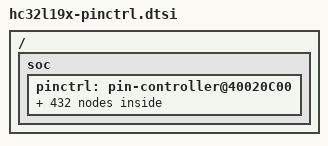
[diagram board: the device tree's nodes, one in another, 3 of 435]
/* Generated by gen-pinctrl.perl, do not edit this file. */
#include <hc32/hc32l19x-pinctrl.h>
/ {
	soc {
		pinctrl: pin-controller@40020C00 {
			/omit-if-no-ref/ uart1_cts_pa0: uart1_cts_pa0 {
				pinmux = <PA00_UART1_CTS>;
			};
			/omit-if-no-ref/ uart1_rts_pa1: uart1_rts_pa1 {
				pinmux = <PA01_UART1_RTS>;
			};
			/omit-if-no-ref/ uart1_txd_pa2: uart1_txd_pa2 {
				pinmux = <PA02_UART1_TXD>;
			};
			/omit-if-no-ref/ uart1_rxd_pa3: uart1_rxd_pa3 {
				pinmux = <PA03_UART1_RXD>;
			};
			/omit-if-no-ref/ spi0_cs_pa4: spi0_cs_pa4 {
				pinmux = <PA04_SPI0_CS>;
				bias-pull-down;
			};
			/omit-if-no-ref/ spi0_sck_pa5: spi0_sck_pa5 {
				pinmux = <PA05_SPI0_SCK>;
				bias-pull-down;
			};
			/omit-if-no-ref/ spi0_miso_pa6: spi0_miso_pa6 {
				pinmux = <PA06_SPI0_MISO>;
				bias-pull-down;
			};
			/omit-if-no-ref/ spi0_mosi_pa7: spi0_mosi_pa7 {
				pinmux = <PA07_SPI0_MOSI>;
				bias-pull-down;
			};
			/omit-if-no-ref/ uart0_txd_pa8: uart0_txd_pa8 {
				pinmux = <PA08_UART0_TXD>;
			};
			/omit-if-no-ref/ uart0_txd_pa9: uart0_txd_pa9 {
				pinmux = <PA09_UART0_TXD>;
			};
			/omit-if-no-ref/ uart0_rxd_pa10: uart0_rxd_pa10 {
				pinmux = <PA10_UART0_RXD>;
			};
			/omit-if-no-ref/ uart0_cts_pa11: uart0_cts_pa11 {
				pinmux = <PA11_UART0_CTS>;
			};
			/omit-if-no-ref/ uart0_rts_pa12: uart0_rts_pa12 {
				pinmux = <PA12_UART0_RTS>;
			};
			/omit-if-no-ref/ ir_out_pa13: ir_out_pa13 {
				pinmux = <PA13_IR_OUT>;
			};
			/omit-if-no-ref/ uart1_txd_pa14: uart1_txd_pa14 {
				pinmux = <PA14_UART1_TXD>;
			};
			/omit-if-no-ref/ spi0_cs_pa15: spi0_cs_pa15 {
				pinmux = <PA15_SPI0_CS>;
				bias-pull-down;
			};
			/omit-if-no-ref/ pca_ch2_pb0: pca_ch2_pb0 {
				pinmux = <PB00_PCA_CH2>;
			};
			/omit-if-no-ref/ pca_ch3_pb1: pca_ch3_pb1 {
				pinmux = <PB01_PCA_CH3>;
			};
			/omit-if-no-ref/ lptim_tog_pb2: lptim_tog_pb2 {
				pinmux = <PB02_LPTIM_TOG>;
			};
			/omit-if-no-ref/ spi0_sck_pb3: spi0_sck_pb3 {
				pinmux = <PB03_SPI0_SCK>;
				bias-pull-down;
			};
			/omit-if-no-ref/ spi0_miso_pb4: spi0_miso_pb4 {
				pinmux = <PB04_SPI0_MISO>;
				bias-pull-down;
			};
			/omit-if-no-ref/ spi0_mosi_pb5: spi0_mosi_pb5 {
				pinmux = <PB05_SPI0_MOSI>;
				bias-pull-down;
			};
			/omit-if-no-ref/ i2c0_scl_pb6: i2c0_scl_pb6 {
				pinmux = <PB06_I2C0_SCL>;
				bias-pull-up;
				drive-open-drain;
			};
			/omit-if-no-ref/ i2c0_sda_pb7: i2c0_sda_pb7 {
				pinmux = <PB07_I2C0_SDA>;
				bias-pull-up;
				drive-open-drain;
			};
			/omit-if-no-ref/ i2c0_scl_pb8: i2c0_scl_pb8 {
				pinmux = <PB08_I2C0_SCL>;
				bias-pull-up;
				drive-open-drain;
			};
			/omit-if-no-ref/ i2c0_sda_pb9: i2c0_sda_pb9 {
				pinmux = <PB09_I2C0_SDA>;
				bias-pull-up;
				drive-open-drain;
			};
			/omit-if-no-ref/ i2c1_scl_pb10: i2c1_scl_pb10 {
				pinmux = <PB10_I2C1_SCL>;
				bias-pull-up;
				drive-open-drain;
			};
			/omit-if-no-ref/ i2c1_sda_pb11: i2c1_sda_pb11 {
				pinmux = <PB11_I2C1_SDA>;
				bias-pull-up;
				drive-open-drain;
			};
			/omit-if-no-ref/ spi1_cs_pb12: spi1_cs_pb12 {
				pinmux = <PB12_SPI1_CS>;
				bias-pull-down;
			};
			/omit-if-no-ref/ spi1_sck_pb13: spi1_sck_pb13 {
				pinmux = <PB13_SPI1_SCK>;
				bias-pull-down;
			};
			/omit-if-no-ref/ spi1_miso_pb14: spi1_miso_pb14 {
				pinmux = <PB14_SPI1_MISO>;
				bias-pull-down;
			};
			/omit-if-no-ref/ spi1_mosi_pb15: spi1_mosi_pb15 {
				pinmux = <PB15_SPI1_MOSI>;
				bias-pull-down;
			};
			/omit-if-no-ref/ lptim_gate_pc0: lptim_gate_pc0 {
				pinmux = <PC00_LPTIM_GATE>;
			};
			/omit-if-no-ref/ lptim_tog_pc1: lptim_tog_pc1 {
				pinmux = <PC01_LPTIM_TOG>;
			};
			/omit-if-no-ref/ spi1_miso_pc2: spi1_miso_pc2 {
				pinmux = <PC02_SPI1_MISO>;
				bias-pull-down;
			};
			/omit-if-no-ref/ spi1_mosi_pc3: spi1_mosi_pc3 {
				pinmux = <PC03_SPI1_MOSI>;
				bias-pull-down;
			};
			/omit-if-no-ref/ lpuart0_txd_pc4: lpuart0_txd_pc4 {
				pinmux = <PC04_LPUART0_TXD>;
			};
			/omit-if-no-ref/ lpuart0_rxd_pc5: lpuart0_rxd_pc5 {
				pinmux = <PC05_LPUART0_RXD>;
			};
			/omit-if-no-ref/ pca_ch0_pc6: pca_ch0_pc6 {
				pinmux = <PC06_PCA_CH0>;
			};
			/omit-if-no-ref/ pca_ch1_pc7: pca_ch1_pc7 {
				pinmux = <PC07_PCA_CH1>;
			};
			/omit-if-no-ref/ pca_ch2_pc8: pca_ch2_pc8 {
				pinmux = <PC08_PCA_CH2>;
			};
			/omit-if-no-ref/ pca_ch3_pc9: pca_ch3_pc9 {
				pinmux = <PC09_PCA_CH3>;
			};
			/omit-if-no-ref/ lpuart1_txd_pc10: lpuart1_txd_pc10 {
				pinmux = <PC10_LPUART1_TXD>;
			};
			/omit-if-no-ref/ lpuart1_rxd_pc11: lpuart1_rxd_pc11 {
				pinmux = <PC11_LPUART1_RXD>;
			};
			/omit-if-no-ref/ lpuart0_txd_pc12: lpuart0_txd_pc12 {
				pinmux = <PC12_LPUART0_TXD>;
			};
			/omit-if-no-ref/ pca_eci_pd2: pca_eci_pd2 {
				pinmux = <PD02_PCA_ECI>;
			};
			/omit-if-no-ref/ uart1_cts_pd3: uart1_cts_pd3 {
				pinmux = <PD03_UART1_CTS>;
			};
			/omit-if-no-ref/ uart1_rts_pd4: uart1_rts_pd4 {
				pinmux = <PD04_UART1_RTS>;
			};
			/omit-if-no-ref/ uart1_txd_pd5: uart1_txd_pd5 {
				pinmux = <PD05_UART1_TXD>;
			};
			/omit-if-no-ref/ uart1_rxd_pd6: uart1_rxd_pd6 {
				pinmux = <PD06_UART1_RXD>;
			};
			/omit-if-no-ref/ uart1_txd_pd7: uart1_txd_pd7 {
				pinmux = <PD07_UART1_TXD>;
			};
			/omit-if-no-ref/ lpuart0_txd_pd8: lpuart0_txd_pd8 {
				pinmux = <PD08_LPUART0_TXD>;
			};
			/omit-if-no-ref/ lpuart0_rxd_pd9: lpuart0_rxd_pd9 {
				pinmux = <PD09_LPUART0_RXD>;
			};
			/omit-if-no-ref/ lpuart0_txd_pd10: lpuart0_txd_pd10 {
				pinmux = <PD10_LPUART0_TXD>;
			};
			/omit-if-no-ref/ lpuart0_cts_pd11: lpuart0_cts_pd11 {
				pinmux = <PD11_LPUART0_CTS>;
			};
			/omit-if-no-ref/ lpuart0_rts_pd12: lpuart0_rts_pd12 {
				pinmux = <PD12_LPUART0_RTS>;
			};
			/omit-if-no-ref/ uart2_rxd_pd13: uart2_rxd_pd13 {
				pinmux = <PD13_UART2_RXD>;
			};
			/omit-if-no-ref/ uart2_txd_pd14: uart2_txd_pd14 {
				pinmux = <PD14_UART2_TXD>;
			};
			/omit-if-no-ref/ tim1_cha_pe0: tim1_cha_pe0 {
				pinmux = <PE00_TIM1_CHA>;
			};
			/omit-if-no-ref/ tim2_cha_pe1: tim2_cha_pe1 {
				pinmux = <PE01_TIM2_CHA>;
			};
			/omit-if-no-ref/ pca_eci_pe2: pca_eci_pe2 {
				pinmux = <PE02_PCA_ECI>;
			};
			/omit-if-no-ref/ pca_ch0_pe3: pca_ch0_pe3 {
				pinmux = <PE03_PCA_CH0>;
			};
			/omit-if-no-ref/ pca_ch1_pe4: pca_ch1_pe4 {
				pinmux = <PE04_PCA_CH1>;
			};
			/omit-if-no-ref/ pca_ch2_pe5: pca_ch2_pe5 {
				pinmux = <PE05_PCA_CH2>;
			};
			/omit-if-no-ref/ pca_ch3_pe6: pca_ch3_pe6 {
				pinmux = <PE06_PCA_CH3>;
			};
			/omit-if-no-ref/ tim3_etr_pe7: tim3_etr_pe7 {
				pinmux = <PE07_TIM3_ETR>;
			};
			/omit-if-no-ref/ tim3_ch0b_pe8: tim3_ch0b_pe8 {
				pinmux = <PE08_TIM3_CH0B>;
			};
			/omit-if-no-ref/ tim3_ch0a_pe9: tim3_ch0a_pe9 {
				pinmux = <PE09_TIM3_CH0A>;
			};
			/omit-if-no-ref/ tim3_ch1b_pe10: tim3_ch1b_pe10 {
				pinmux = <PE10_TIM3_CH1B>;
			};
			/omit-if-no-ref/ tim3_ch1a_pe11: tim3_ch1a_pe11 {
				pinmux = <PE11_TIM3_CH1A>;
			};
			/omit-if-no-ref/ tim3_ch2b_pe12: tim3_ch2b_pe12 {
				pinmux = <PE12_TIM3_CH2B>;
			};
			/omit-if-no-ref/ tim3_ch2a_pe13: tim3_ch2a_pe13 {
				pinmux = <PE13_TIM3_CH2A>;
			};
			/omit-if-no-ref/ tim3_ch0b_pe14: tim3_ch0b_pe14 {
				pinmux = <PE14_TIM3_CH0B>;
			};
			/omit-if-no-ref/ tim3_bk_pe15: tim3_bk_pe15 {
				pinmux = <PE15_TIM3_BK>;
			};
			/omit-if-no-ref/ i2c0_sda_pf0: i2c0_sda_pf0 {
				pinmux = <PF00_I2C0_SDA>;
				bias-pull-up;
				drive-open-drain;
			};
			/omit-if-no-ref/ i2c0_scl_pf1: i2c0_scl_pf1 {
				pinmux = <PF01_I2C0_SCL>;
				bias-pull-up;
				drive-open-drain;
			};
			/omit-if-no-ref/ i2c1_scl_pf6: i2c1_scl_pf6 {
				pinmux = <PF06_I2C1_SCL>;
				bias-pull-up;
				drive-open-drain;
			};
			/omit-if-no-ref/ i2c1_sda_pf7: i2c1_sda_pf7 {
				pinmux = <PF07_I2C1_SDA>;
				bias-pull-up;
				drive-open-drain;
			};
			/omit-if-no-ref/ tim0_cha_pf9: tim0_cha_pf9 {
				pinmux = <PF09_TIM0_CHA>;
			};
			/omit-if-no-ref/ tim0_chb_pf10: tim0_chb_pf10 {
				pinmux = <PF10_TIM0_CHB>;
			};
			/omit-if-no-ref/ lpuart1_txd_pa0: lpuart1_txd_pa0 {
				pinmux = <PA00_LPUART1_TXD>;
			};
			/omit-if-no-ref/ lpuart1_rxd_pa1: lpuart1_rxd_pa1 {
				pinmux = <PA01_LPUART1_RXD>;
			};
			/omit-if-no-ref/ tim0_cha_pa2: tim0_cha_pa2 {
				pinmux = <PA02_TIM0_CHA>;
			};
			/omit-if-no-ref/ tim0_gate_pa3: tim0_gate_pa3 {
				pinmux = <PA03_TIM0_GATE>;
			};
			/omit-if-no-ref/ uart1_txd_pa4: uart1_txd_pa4 {
				pinmux = <PA04_UART1_TXD>;
			};
			/omit-if-no-ref/ tim0_etr_pa5: tim0_etr_pa5 {
				pinmux = <PA05_TIM0_ETR>;
			};
			/omit-if-no-ref/ pca_ch0_pa6: pca_ch0_pa6 {
				pinmux = <PA06_PCA_CH0>;
			};
			/omit-if-no-ref/ pca_ch1_pa7: pca_ch1_pa7 {
				pinmux = <PA07_PCA_CH1>;
			};
			/omit-if-no-ref/ tim3_ch0a_pa8: tim3_ch0a_pa8 {
				pinmux = <PA08_TIM3_CH0A>;
			};
			/omit-if-no-ref/ tim3_ch1a_pa9: tim3_ch1a_pa9 {
				pinmux = <PA09_TIM3_CH1A>;
			};
			/omit-if-no-ref/ tim3_ch2a_pa10: tim3_ch2a_pa10 {
				pinmux = <PA10_TIM3_CH2A>;
			};
			/omit-if-no-ref/ tim3_gate_pa11: tim3_gate_pa11 {
				pinmux = <PA11_TIM3_GATE>;
			};
			/omit-if-no-ref/ tim3_etr_pa12: tim3_etr_pa12 {
				pinmux = <PA12_TIM3_ETR>;
			};
			/omit-if-no-ref/ uart0_rxd_pa13: uart0_rxd_pa13 {
				pinmux = <PA13_UART0_RXD>;
			};
			/omit-if-no-ref/ uart0_txd_pa14: uart0_txd_pa14 {
				pinmux = <PA14_UART0_TXD>;
			};
			/omit-if-no-ref/ uart1_rxd_pa15: uart1_rxd_pa15 {
				pinmux = <PA15_UART1_RXD>;
			};
			/omit-if-no-ref/ tim3_ch1b_pb0: tim3_ch1b_pb0 {
				pinmux = <PB00_TIM3_CH1B>;
			};
			/omit-if-no-ref/ pclk_out_pb1: pclk_out_pb1 {
				pinmux = <PB01_PCLK_OUT>;
			};
			/omit-if-no-ref/ pca_eci_pb2: pca_eci_pb2 {
				pinmux = <PB02_PCA_ECI>;
			};
			/omit-if-no-ref/ tim0_chb_pb3: tim0_chb_pb3 {
				pinmux = <PB03_TIM0_CHB>;
			};
			/omit-if-no-ref/ pca_ch0_pb4: pca_ch0_pb4 {
				pinmux = <PB04_PCA_CH0>;
			};
			/omit-if-no-ref/ uart0_txd_pb6: uart0_txd_pb6 {
				pinmux = <PB06_UART0_TXD>;
			};
			/omit-if-no-ref/ uart0_rxd_pb7: uart0_rxd_pb7 {
				pinmux = <PB07_UART0_RXD>;
			};
			/omit-if-no-ref/ tim1_cha_pb8: tim1_cha_pb8 {
				pinmux = <PB08_TIM1_CHA>;
			};
			/omit-if-no-ref/ ir_out_pb9: ir_out_pb9 {
				pinmux = <PB09_IR_OUT>;
			};
			/omit-if-no-ref/ spi1_sck_pb10: spi1_sck_pb10 {
				pinmux = <PB10_SPI1_SCK>;
				bias-pull-down;
			};
			/omit-if-no-ref/ tim1_chb_pb11: tim1_chb_pb11 {
				pinmux = <PB11_TIM1_CHB>;
			};
			/omit-if-no-ref/ tim3_bk_pb12: tim3_bk_pb12 {
				pinmux = <PB12_TIM3_BK>;
			};
			/omit-if-no-ref/ i2c1_scl_pb13: i2c1_scl_pb13 {
				pinmux = <PB13_I2C1_SCL>;
				bias-pull-up;
				drive-open-drain;
			};
			/omit-if-no-ref/ i2c1_sda_pb14: i2c1_sda_pb14 {
				pinmux = <PB14_I2C1_SDA>;
				bias-pull-up;
				drive-open-drain;
			};
			/omit-if-no-ref/ tim3_ch2b_pb15: tim3_ch2b_pb15 {
				pinmux = <PB15_TIM3_CH2B>;
			};
			/omit-if-no-ref/ pcnt_s0_pc0: pcnt_s0_pc0 {
				pinmux = <PC00_PCNT_S0>;
			};
			/omit-if-no-ref/ tim5_chb_pc1: tim5_chb_pc1 {
				pinmux = <PC01_TIM5_CHB>;
			};
			/omit-if-no-ref/ lptim_togn_pc2: lptim_togn_pc2 {
				pinmux = <PC02_LPTIM_TOGN>;
			};
			/omit-if-no-ref/ lptim_etr_pc3: lptim_etr_pc3 {
				pinmux = <PC03_LPTIM_ETR>;
			};
			/omit-if-no-ref/ tim2_etr_pc4: tim2_etr_pc4 {
				pinmux = <PC04_TIM2_ETR>;
			};
			/omit-if-no-ref/ tim6_chb_pc5: tim6_chb_pc5 {
				pinmux = <PC05_TIM6_CHB>;
			};
			/omit-if-no-ref/ tim4_cha_pc6: tim4_cha_pc6 {
				pinmux = <PC06_TIM4_CHA>;
			};
			/omit-if-no-ref/ tim5_cha_pc7: tim5_cha_pc7 {
				pinmux = <PC07_TIM5_CHA>;
			};
			/omit-if-no-ref/ tim6_cha_pc8: tim6_cha_pc8 {
				pinmux = <PC08_TIM6_CHA>;
			};
			/omit-if-no-ref/ tim4_chb_pc9: tim4_chb_pc9 {
				pinmux = <PC09_TIM4_CHB>;
			};
			/omit-if-no-ref/ lpuart0_txd_pc10: lpuart0_txd_pc10 {
				pinmux = <PC10_LPUART0_TXD>;
			};
			/omit-if-no-ref/ lpuart0_rxd_pc11: lpuart0_rxd_pc11 {
				pinmux = <PC11_LPUART0_RXD>;
			};
			/omit-if-no-ref/ lpuart1_txd_pc12: lpuart1_txd_pc12 {
				pinmux = <PC12_LPUART1_TXD>;
			};
			/omit-if-no-ref/ rtc_1hz_pc13: rtc_1hz_pc13 {
				pinmux = <PC13_RTC_1HZ>;
			};
			/omit-if-no-ref/ spi1_cs_pd0: spi1_cs_pd0 {
				pinmux = <PD00_SPI1_CS>;
				bias-pull-down;
			};
			/omit-if-no-ref/ spi1_sck_pd1: spi1_sck_pd1 {
				pinmux = <PD01_SPI1_SCK>;
				bias-pull-down;
			};
			/omit-if-no-ref/ lpuart0_rts_pd2: lpuart0_rts_pd2 {
				pinmux = <PD02_LPUART0_RTS>;
			};
			/omit-if-no-ref/ spi1_miso_pd3: spi1_miso_pd3 {
				pinmux = <PD03_SPI1_MISO>;
				bias-pull-down;
			};
			/omit-if-no-ref/ spi1_mosi_pd4: spi1_mosi_pd4 {
				pinmux = <PD04_SPI1_MOSI>;
				bias-pull-down;
			};
			/omit-if-no-ref/ lptim1_gate_pd5: lptim1_gate_pd5 {
				pinmux = <PD05_LPTIM1_GATE>;
			};
			/omit-if-no-ref/ lptim1_etr_pd6: lptim1_etr_pd6 {
				pinmux = <PD06_LPTIM1_ETR>;
			};
			/omit-if-no-ref/ uart2_rts_pd12: uart2_rts_pd12 {
				pinmux = <PD12_UART2_RTS>;
			};
			/omit-if-no-ref/ uart2_cts_pd15: uart2_cts_pd15 {
				pinmux = <PD15_UART2_CTS>;
			};
			/omit-if-no-ref/ lptim1_gate_pe7: lptim1_gate_pe7 {
				pinmux = <PE07_LPTIM1_GATE>;
			};
			/omit-if-no-ref/ lptim1_etr_pe8: lptim1_etr_pe8 {
				pinmux = <PE08_LPTIM1_ETR>;
			};
			/omit-if-no-ref/ lptim1_tog_pe9: lptim1_tog_pe9 {
				pinmux = <PE09_LPTIM1_TOG>;
			};
			/omit-if-no-ref/ lptim1_togn_pe10: lptim1_togn_pe10 {
				pinmux = <PE10_LPTIM1_TOGN>;
			};
			/omit-if-no-ref/ spi0_cs_pe12: spi0_cs_pe12 {
				pinmux = <PE12_SPI0_CS>;
				bias-pull-down;
			};
			/omit-if-no-ref/ spi0_sck_pe13: spi0_sck_pe13 {
				pinmux = <PE13_SPI0_SCK>;
				bias-pull-down;
			};
			/omit-if-no-ref/ spi0_miso_pe14: spi0_miso_pe14 {
				pinmux = <PE14_SPI0_MISO>;
				bias-pull-down;
			};
			/omit-if-no-ref/ spi0_mosi_pe15: spi0_mosi_pe15 {
				pinmux = <PE15_SPI0_MOSI>;
				bias-pull-down;
			};
			/omit-if-no-ref/ tim4_chb_pf1: tim4_chb_pf1 {
				pinmux = <PF01_TIM4_CHB>;
			};
			/omit-if-no-ref/ lpuart1_cts_pf6: lpuart1_cts_pf6 {
				pinmux = <PF06_LPUART1_CTS>;
			};
			/omit-if-no-ref/ lpuart1_rts_pf7: lpuart1_rts_pf7 {
				pinmux = <PF07_LPUART1_RTS>;
			};
			/omit-if-no-ref/ tim0_etr_pa0: tim0_etr_pa0 {
				pinmux = <PA00_TIM0_ETR>;
			};
			/omit-if-no-ref/ tim0_chb_pa1: tim0_chb_pa1 {
				pinmux = <PA01_TIM0_CHB>;
			};
			/omit-if-no-ref/ vc1_out_pa2: vc1_out_pa2 {
				pinmux = <PA02_VC1_OUT>;
			};
			/omit-if-no-ref/ tim1_chb_pa3: tim1_chb_pa3 {
				pinmux = <PA03_TIM1_CHB>;
			};
			/omit-if-no-ref/ pca_ch4_pa4: pca_ch4_pa4 {
				pinmux = <PA04_PCA_CH4>;
			};
			/omit-if-no-ref/ pca_eci_pa5: pca_eci_pa5 {
				pinmux = <PA05_PCA_ECI>;
			};
			/omit-if-no-ref/ tim3_bk_pa6: tim3_bk_pa6 {
				pinmux = <PA06_TIM3_BK>;
			};
			/omit-if-no-ref/ hclk_out_pa7: hclk_out_pa7 {
				pinmux = <PA07_HCLK_OUT>;
			};
			/omit-if-no-ref/ tim0_bk_pa9: tim0_bk_pa9 {
				pinmux = <PA09_TIM0_BK>;
			};
			/omit-if-no-ref/ tim2_bk_pa10: tim2_bk_pa10 {
				pinmux = <PA10_TIM2_BK>;
			};
			/omit-if-no-ref/ i2c1_scl_pa11: i2c1_scl_pa11 {
				pinmux = <PA11_I2C1_SCL>;
				bias-pull-up;
				drive-open-drain;
			};
			/omit-if-no-ref/ i2c1_sda_pa12: i2c1_sda_pa12 {
				pinmux = <PA12_I2C1_SDA>;
				bias-pull-up;
				drive-open-drain;
			};
			/omit-if-no-ref/ lvd_out_pa13: lvd_out_pa13 {
				pinmux = <PA13_LVD_OUT>;
			};
			/omit-if-no-ref/ tim3_ch2a_pa14: tim3_ch2a_pa14 {
				pinmux = <PA14_TIM3_CH2A>;
			};
			/omit-if-no-ref/ lpuart1_rts_pa15: lpuart1_rts_pa15 {
				pinmux = <PA15_LPUART1_RTS>;
			};
			/omit-if-no-ref/ lpuart0_txd_pb0: lpuart0_txd_pb0 {
				pinmux = <PB00_LPUART0_TXD>;
			};
			/omit-if-no-ref/ tim3_ch2b_pb1: tim3_ch2b_pb1 {
				pinmux = <PB01_TIM3_CH2B>;
			};
			/omit-if-no-ref/ lpuart1_txd_pb2: lpuart1_txd_pb2 {
				pinmux = <PB02_LPUART1_TXD>;
			};
			/omit-if-no-ref/ tim1_gate_pb3: tim1_gate_pb3 {
				pinmux = <PB03_TIM1_GATE>;
			};
			/omit-if-no-ref/ tim2_bk_pb4: tim2_bk_pb4 {
				pinmux = <PB04_TIM2_BK>;
			};
			/omit-if-no-ref/ tim1_bk_pb5: tim1_bk_pb5 {
				pinmux = <PB05_TIM1_BK>;
			};
			/omit-if-no-ref/ tim1_chb_pb6: tim1_chb_pb6 {
				pinmux = <PB06_TIM1_CHB>;
			};
			/omit-if-no-ref/ tim2_chb_pb7: tim2_chb_pb7 {
				pinmux = <PB07_TIM2_CHB>;
			};
			/omit-if-no-ref/ spi1_cs_pb9: spi1_cs_pb9 {
				pinmux = <PB09_SPI1_CS>;
				bias-pull-down;
			};
			/omit-if-no-ref/ tim1_cha_pb10: tim1_cha_pb10 {
				pinmux = <PB10_TIM1_CHA>;
			};
			/omit-if-no-ref/ lpuart0_rxd_pb11: lpuart0_rxd_pb11 {
				pinmux = <PB11_LPUART0_RXD>;
			};
			/omit-if-no-ref/ lpuart0_txd_pb12: lpuart0_txd_pb12 {
				pinmux = <PB12_LPUART0_TXD>;
			};
			/omit-if-no-ref/ tim3_ch0b_pb13: tim3_ch0b_pb13 {
				pinmux = <PB13_TIM3_CH0B>;
			};
			/omit-if-no-ref/ tim3_ch1b_pb14: tim3_ch1b_pb14 {
				pinmux = <PB14_TIM3_CH1B>;
			};
			/omit-if-no-ref/ tim0_chb_pb15: tim0_chb_pb15 {
				pinmux = <PB15_TIM0_CHB>;
			};
			/omit-if-no-ref/ uart1_cts_pc0: uart1_cts_pc0 {
				pinmux = <PC00_UART1_CTS>;
			};
			/omit-if-no-ref/ uart1_rts_pc1: uart1_rts_pc1 {
				pinmux = <PC01_UART1_RTS>;
			};
			/omit-if-no-ref/ pcnt_s1_pc2: pcnt_s1_pc2 {
				pinmux = <PC02_PCNT_S1>;
			};
			/omit-if-no-ref/ lptim_togn_pc3: lptim_togn_pc3 {
				pinmux = <PC03_LPTIM_TOGN>;
			};
			/omit-if-no-ref/ ir_out_pc4: ir_out_pc4 {
				pinmux = <PC04_IR_OUT>;
			};
			/omit-if-no-ref/ pca_ch4_pc5: pca_ch4_pc5 {
				pinmux = <PC05_PCA_CH4>;
			};
			/omit-if-no-ref/ tim2_cha_pc6: tim2_cha_pc6 {
				pinmux = <PC06_TIM2_CHA>;
			};
			/omit-if-no-ref/ tim2_chb_pc7: tim2_chb_pc7 {
				pinmux = <PC07_TIM2_CHB>;
			};
			/omit-if-no-ref/ tim2_etr_pc8: tim2_etr_pc8 {
				pinmux = <PC08_TIM2_ETR>;
			};
			/omit-if-no-ref/ tim1_etr_pc9: tim1_etr_pc9 {
				pinmux = <PC09_TIM1_ETR>;
			};
			/omit-if-no-ref/ pca_ch2_pc10: pca_ch2_pc10 {
				pinmux = <PC10_PCA_CH2>;
			};
			/omit-if-no-ref/ pca_ch3_pc11: pca_ch3_pc11 {
				pinmux = <PC11_PCA_CH3>;
			};
			/omit-if-no-ref/ pca_ch4_pc12: pca_ch4_pc12 {
				pinmux = <PC12_PCA_CH4>;
			};
			/omit-if-no-ref/ tim3_ch1b_pc13: tim3_ch1b_pc13 {
				pinmux = <PC13_TIM3_CH1B>;
			};
			/omit-if-no-ref/ tim1_etr_pd2: tim1_etr_pd2 {
				pinmux = <PD02_TIM1_ETR>;
			};
			/omit-if-no-ref/ lptim1_tog_pd3: lptim1_tog_pd3 {
				pinmux = <PD03_LPTIM1_TOG>;
			};
			/omit-if-no-ref/ lptim1_togn_pd4: lptim1_togn_pd4 {
				pinmux = <PD04_LPTIM1_TOGN>;
			};
			/omit-if-no-ref/ uart3_cts_pe12: uart3_cts_pe12 {
				pinmux = <PE12_UART3_CTS>;
			};
			/omit-if-no-ref/ uart3_rts_pe13: uart3_rts_pe13 {
				pinmux = <PE13_UART3_RTS>;
			};
			/omit-if-no-ref/ uart3_rxd_pe14: uart3_rxd_pe14 {
				pinmux = <PE14_UART3_RXD>;
			};
			/omit-if-no-ref/ uart3_txd_pe15: uart3_txd_pe15 {
				pinmux = <PE15_UART3_TXD>;
			};
			/omit-if-no-ref/ uart1_txd_pf0: uart1_txd_pf0 {
				pinmux = <PF00_UART1_TXD>;
			};
			/omit-if-no-ref/ uart1_rxd_pf1: uart1_rxd_pf1 {
				pinmux = <PF01_UART1_RXD>;
			};
			/omit-if-no-ref/ uart0_cts_pf6: uart0_cts_pf6 {
				pinmux = <PF06_UART0_CTS>;
			};
			/omit-if-no-ref/ uart0_rts_pf7: uart0_rts_pf7 {
				pinmux = <PF07_UART0_RTS>;
			};
			/omit-if-no-ref/ vc0_out_pa0: vc0_out_pa0 {
				pinmux = <PA00_VC0_OUT>;
			};
			/omit-if-no-ref/ tim1_etr_pa1: tim1_etr_pa1 {
				pinmux = <PA01_TIM1_ETR>;
			};
			/omit-if-no-ref/ tim1_cha_pa2: tim1_cha_pa2 {
				pinmux = <PA02_TIM1_CHA>;
			};
			/omit-if-no-ref/ tim2_chb_pa3: tim2_chb_pa3 {
				pinmux = <PA03_TIM2_CHB>;
			};
			/omit-if-no-ref/ tim2_etr_pa4: tim2_etr_pa4 {
				pinmux = <PA04_TIM2_ETR>;
			};
			/omit-if-no-ref/ tim0_cha_pa5: tim0_cha_pa5 {
				pinmux = <PA05_TIM0_CHA>;
			};
			/omit-if-no-ref/ tim1_cha_pa6: tim1_cha_pa6 {
				pinmux = <PA06_TIM1_CHA>;
			};
			/omit-if-no-ref/ tim3_ch0b_pa7: tim3_ch0b_pa7 {
				pinmux = <PA07_TIM3_CH0B>;
			};
			/omit-if-no-ref/ i2c0_scl_pa9: i2c0_scl_pa9 {
				pinmux = <PA09_I2C0_SCL>;
				bias-pull-up;
				drive-open-drain;
			};
			/omit-if-no-ref/ i2c0_sda_pa10: i2c0_sda_pa10 {
				pinmux = <PA10_I2C0_SDA>;
				bias-pull-up;
				drive-open-drain;
			};
			/omit-if-no-ref/ tim3_etr_pa13: tim3_etr_pa13 {
				pinmux = <PA13_TIM3_ETR>;
			};
			/omit-if-no-ref/ lvd_out_pa14: lvd_out_pa14 {
				pinmux = <PA14_LVD_OUT>;
			};
			/omit-if-no-ref/ tim0_etr_pa15: tim0_etr_pa15 {
				pinmux = <PA15_TIM0_ETR>;
			};
			/omit-if-no-ref/ tim5_chb_pb0: tim5_chb_pb0 {
				pinmux = <PB00_TIM5_CHB>;
			};
			/omit-if-no-ref/ tim6_chb_pb1: tim6_chb_pb1 {
				pinmux = <PB01_TIM6_CHB>;
			};
			/omit-if-no-ref/ tim4_cha_pb2: tim4_cha_pb2 {
				pinmux = <PB02_TIM4_CHA>;
			};
			/omit-if-no-ref/ tim3_ch0a_pb3: tim3_ch0a_pb3 {
				pinmux = <PB03_TIM3_CH0A>;
			};
			/omit-if-no-ref/ uart0_cts_pb4: uart0_cts_pb4 {
				pinmux = <PB04_UART0_CTS>;
			};
			/omit-if-no-ref/ pca_ch1_pb5: pca_ch1_pb5 {
				pinmux = <PB05_PCA_CH1>;
			};
			/omit-if-no-ref/ tim0_cha_pb6: tim0_cha_pb6 {
				pinmux = <PB06_TIM0_CHA>;
			};
			/omit-if-no-ref/ lpuart1_cts_pb7: lpuart1_cts_pb7 {
				pinmux = <PB07_LPUART1_CTS>;
			};
			/omit-if-no-ref/ tim2_cha_pb8: tim2_cha_pb8 {
				pinmux = <PB08_TIM2_CHA>;
			};
			/omit-if-no-ref/ tim2_cha_pb9: tim2_cha_pb9 {
				pinmux = <PB09_TIM2_CHA>;
			};
			/omit-if-no-ref/ lpuart0_txd_pb10: lpuart0_txd_pb10 {
				pinmux = <PB10_LPUART0_TXD>;
			};
			/omit-if-no-ref/ tim2_gate_pb11: tim2_gate_pb11 {
				pinmux = <PB11_TIM2_GATE>;
			};
			/omit-if-no-ref/ tim0_bk_pb12: tim0_bk_pb12 {
				pinmux = <PB12_TIM0_BK>;
			};
			/omit-if-no-ref/ lpuart0_cts_pb13: lpuart0_cts_pb13 {
				pinmux = <PB13_LPUART0_CTS>;
			};
			/omit-if-no-ref/ tim0_cha_pb14: tim0_cha_pb14 {
				pinmux = <PB14_TIM0_CHA>;
			};
			/omit-if-no-ref/ tim0_gate_pb15: tim0_gate_pb15 {
				pinmux = <PB15_TIM0_GATE>;
			};
			/omit-if-no-ref/ uart2_rts_pc0: uart2_rts_pc0 {
				pinmux = <PC00_UART2_RTS>;
			};
			/omit-if-no-ref/ pcnt_s0fo_pc1: pcnt_s0fo_pc1 {
				pinmux = <PC01_PCNT_S0FO>;
			};
			/omit-if-no-ref/ uart2_rxd_pc2: uart2_rxd_pc2 {
				pinmux = <PC02_UART2_RXD>;
			};
			/omit-if-no-ref/ pcnt_s1fo_pc3: pcnt_s1fo_pc3 {
				pinmux = <PC03_PCNT_S1FO>;
			};
			/omit-if-no-ref/ vc2_out_pc4: vc2_out_pc4 {
				pinmux = <PC04_VC2_OUT>;
			};
			/omit-if-no-ref/ lptim1_gate_pc6: lptim1_gate_pc6 {
				pinmux = <PC06_LPTIM1_GATE>;
			};
			/omit-if-no-ref/ lptim1_etr_pc7: lptim1_etr_pc7 {
				pinmux = <PC07_LPTIM1_ETR>;
			};
			/omit-if-no-ref/ lptim1_tog_pc8: lptim1_tog_pc8 {
				pinmux = <PC08_LPTIM1_TOG>;
			};
			/omit-if-no-ref/ lptim1_togn_pc9: lptim1_togn_pc9 {
				pinmux = <PC09_LPTIM1_TOGN>;
			};
			/omit-if-no-ref/ pcnt_s0fo_pc11: pcnt_s0fo_pc11 {
				pinmux = <PC11_PCNT_S0FO>;
			};
			/omit-if-no-ref/ pcnt_s1fo_pc12: pcnt_s1fo_pc12 {
				pinmux = <PC12_PCNT_S1FO>;
			};
			/omit-if-no-ref/ tim1_cha_pa0: tim1_cha_pa0 {
				pinmux = <PA00_TIM1_CHA>;
			};
			/omit-if-no-ref/ tim1_chb_pa1: tim1_chb_pa1 {
				pinmux = <PA01_TIM1_CHB>;
			};
			/omit-if-no-ref/ tim2_cha_pa2: tim2_cha_pa2 {
				pinmux = <PA02_TIM2_CHA>;
			};
			/omit-if-no-ref/ spi1_cs_pa3: spi1_cs_pa3 {
				pinmux = <PA03_SPI1_CS>;
				bias-pull-down;
			};
			/omit-if-no-ref/ tim5_cha_pa4: tim5_cha_pa4 {
				pinmux = <PA04_TIM5_CHA>;
			};
			/omit-if-no-ref/ tim5_chb_pa5: tim5_chb_pa5 {
				pinmux = <PA05_TIM5_CHB>;
			};
			/omit-if-no-ref/ vc0_out_pa6: vc0_out_pa6 {
				pinmux = <PA06_VC0_OUT>;
			};
			/omit-if-no-ref/ tim2_cha_pa7: tim2_cha_pa7 {
				pinmux = <PA07_TIM2_CHA>;
			};
			/omit-if-no-ref/ tim1_gate_pa8: tim1_gate_pa8 {
				pinmux = <PA08_TIM1_GATE>;
			};
			/omit-if-no-ref/ tim2_gate_pa10: tim2_gate_pa10 {
				pinmux = <PA10_TIM2_GATE>;
			};
			/omit-if-no-ref/ vc0_out_pa11: vc0_out_pa11 {
				pinmux = <PA11_VC0_OUT>;
			};
			/omit-if-no-ref/ vc1_out_pa12: vc1_out_pa12 {
				pinmux = <PA12_VC1_OUT>;
			};
			/omit-if-no-ref/ rtc_1hz_pa13: rtc_1hz_pa13 {
				pinmux = <PA13_RTC_1HZ>;
			};
			/omit-if-no-ref/ rch_out_pa14: rch_out_pa14 {
				pinmux = <PA14_RCH_OUT>;
			};
			/omit-if-no-ref/ tim0_cha_pa15: tim0_cha_pa15 {
				pinmux = <PA15_TIM0_CHA>;
			};
			/omit-if-no-ref/ rch_out_pb0: rch_out_pb0 {
				pinmux = <PB00_RCH_OUT>;
			};
			/omit-if-no-ref/ lpuart0_rts_pb1: lpuart0_rts_pb1 {
				pinmux = <PB01_LPUART0_RTS>;
			};
			/omit-if-no-ref/ tim1_bk_pb2: tim1_bk_pb2 {
				pinmux = <PB02_TIM1_BK>;
			};
			/omit-if-no-ref/ lptim_gate_pb3: lptim_gate_pb3 {
				pinmux = <PB03_LPTIM_GATE>;
			};
			/omit-if-no-ref/ tim2_gate_pb4: tim2_gate_pb4 {
				pinmux = <PB04_TIM2_GATE>;
			};
			/omit-if-no-ref/ lptim_gate_pb5: lptim_gate_pb5 {
				pinmux = <PB05_LPTIM_GATE>;
			};
			/omit-if-no-ref/ lptim_etr_pb6: lptim_etr_pb6 {
				pinmux = <PB06_LPTIM_ETR>;
			};
			/omit-if-no-ref/ tim0_chb_pb7: tim0_chb_pb7 {
				pinmux = <PB07_TIM0_CHB>;
			};
			/omit-if-no-ref/ tim0_gate_pb8: tim0_gate_pb8 {
				pinmux = <PB08_TIM0_GATE>;
			};
			/omit-if-no-ref/ tim3_ch1a_pb10: tim3_ch1a_pb10 {
				pinmux = <PB10_TIM3_CH1A>;
			};
			/omit-if-no-ref/ tim6_cha_pb11: tim6_cha_pb11 {
				pinmux = <PB11_TIM6_CHA>;
			};
			/omit-if-no-ref/ tim1_cha_pb13: tim1_cha_pb13 {
				pinmux = <PB13_TIM1_CHA>;
			};
			/omit-if-no-ref/ rtc_1hz_pb14: rtc_1hz_pb14 {
				pinmux = <PB14_RTC_1HZ>;
			};
			/omit-if-no-ref/ uart2_txd_pc3: uart2_txd_pc3 {
				pinmux = <PC03_UART2_TXD>;
			};
			/omit-if-no-ref/ tim3_etr_pa0: tim3_etr_pa0 {
				pinmux = <PA00_TIM3_ETR>;
			};
			/omit-if-no-ref/ hclk_out_pa1: hclk_out_pa1 {
				pinmux = <PA01_HCLK_OUT>;
			};
			/omit-if-no-ref/ pclk_out_pa2: pclk_out_pa2 {
				pinmux = <PA02_PCLK_OUT>;
			};
			/omit-if-no-ref/ tim3_ch1a_pa3: tim3_ch1a_pa3 {
				pinmux = <PA03_TIM3_CH1A>;
			};
			/omit-if-no-ref/ lvd_out_pa4: lvd_out_pa4 {
				pinmux = <PA04_LVD_OUT>;
			};
			/omit-if-no-ref/ xtl_out_pa5: xtl_out_pa5 {
				pinmux = <PA05_XTL_OUT>;
			};
			/omit-if-no-ref/ tim3_gate_pa6: tim3_gate_pa6 {
				pinmux = <PA06_TIM3_GATE>;
			};
			/omit-if-no-ref/ vc1_out_pa7: vc1_out_pa7 {
				pinmux = <PA07_VC1_OUT>;
			};
			/omit-if-no-ref/ tim4_cha_pa8: tim4_cha_pa8 {
				pinmux = <PA08_TIM4_CHA>;
			};
			/omit-if-no-ref/ hclk_out_pa9: hclk_out_pa9 {
				pinmux = <PA09_HCLK_OUT>;
			};
			/omit-if-no-ref/ pclk_out_pa10: pclk_out_pa10 {
				pinmux = <PA10_PCLK_OUT>;
			};
			/omit-if-no-ref/ spi0_miso_pa11: spi0_miso_pa11 {
				pinmux = <PA11_SPI0_MISO>;
				bias-pull-down;
			};
			/omit-if-no-ref/ spi0_mosi_pa12: spi0_mosi_pa12 {
				pinmux = <PA12_SPI0_MOSI>;
				bias-pull-down;
			};
			/omit-if-no-ref/ pcnt_s1_pa13: pcnt_s1_pa13 {
				pinmux = <PA13_PCNT_S1>;
			};
			/omit-if-no-ref/ rcl_out_pa14: rcl_out_pa14 {
				pinmux = <PA14_RCL_OUT>;
			};
			/omit-if-no-ref/ tim3_ch1a_pa15: tim3_ch1a_pa15 {
				pinmux = <PA15_TIM3_CH1A>;
			};
			/omit-if-no-ref/ rcl_out_pb0: rcl_out_pb0 {
				pinmux = <PB00_RCL_OUT>;
			};
			/omit-if-no-ref/ vc2_out_pb1: vc2_out_pb1 {
				pinmux = <PB01_VC2_OUT>;
			};
			/omit-if-no-ref/ tim0_bk_pb2: tim0_bk_pb2 {
				pinmux = <PB02_TIM0_BK>;
			};
			/omit-if-no-ref/ xtl_out_pb3: xtl_out_pb3 {
				pinmux = <PB03_XTL_OUT>;
			};
			/omit-if-no-ref/ tim3_ch0b_pb4: tim3_ch0b_pb4 {
				pinmux = <PB04_TIM3_CH0B>;
			};
			/omit-if-no-ref/ pcnt_s0_pb5: pcnt_s0_pb5 {
				pinmux = <PB05_PCNT_S0>;
			};
			/omit-if-no-ref/ tim3_ch0a_pb6: tim3_ch0a_pb6 {
				pinmux = <PB06_TIM3_CH0A>;
			};
			/omit-if-no-ref/ lptim_togn_pb7: lptim_togn_pb7 {
				pinmux = <PB07_LPTIM_TOGN>;
			};
			/omit-if-no-ref/ tim3_ch2a_pb8: tim3_ch2a_pb8 {
				pinmux = <PB08_TIM3_CH2A>;
			};
			/omit-if-no-ref/ tim2_chb_pb9: tim2_chb_pb9 {
				pinmux = <PB09_TIM2_CHB>;
			};
			/omit-if-no-ref/ lpuart1_rts_pb10: lpuart1_rts_pb10 {
				pinmux = <PB10_LPUART1_RTS>;
			};
			/omit-if-no-ref/ lpuart1_cts_pb11: lpuart1_cts_pb11 {
				pinmux = <PB11_LPUART1_CTS>;
			};
			/omit-if-no-ref/ lpuart0_rts_pb12: lpuart0_rts_pb12 {
				pinmux = <PB12_LPUART0_RTS>;
			};
			/omit-if-no-ref/ tim1_gate_pb13: tim1_gate_pb13 {
				pinmux = <PB13_TIM1_GATE>;
			};
			/omit-if-no-ref/ lpuart0_rts_pb14: lpuart0_rts_pb14 {
				pinmux = <PB14_LPUART0_RTS>;
			};
			/omit-if-no-ref/ uart2_cts_pc1: uart2_cts_pc1 {
				pinmux = <PC01_UART2_CTS>;
			};
			/omit-if-no-ref/ uart3_rxd_pc6: uart3_rxd_pc6 {
				pinmux = <PC06_UART3_RXD>;
			};
			/omit-if-no-ref/ uart3_txd_pc7: uart3_txd_pc7 {
				pinmux = <PC07_UART3_TXD>;
			};
			/omit-if-no-ref/ uart3_cts_pc8: uart3_cts_pc8 {
				pinmux = <PC08_UART3_CTS>;
			};
			/omit-if-no-ref/ uart3_rts_pc9: uart3_rts_pc9 {
				pinmux = <PC09_UART3_RTS>;
			};
			/omit-if-no-ref/ tim0_cha_pa0: tim0_cha_pa0 {
				pinmux = <PA00_TIM0_CHA>;
			};
			/omit-if-no-ref/ spi1_mosi_pa1: spi1_mosi_pa1 {
				pinmux = <PA01_SPI1_MOSI>;
				bias-pull-down;
			};
			/omit-if-no-ref/ spi1_miso_pa2: spi1_miso_pa2 {
				pinmux = <PA02_SPI1_MISO>;
				bias-pull-down;
			};
			/omit-if-no-ref/ tim5_cha_pa3: tim5_cha_pa3 {
				pinmux = <PA03_TIM5_CHA>;
			};
			/omit-if-no-ref/ tim3_ch2b_pa4: tim3_ch2b_pa4 {
				pinmux = <PA04_TIM3_CH2B>;
			};
			/omit-if-no-ref/ xth_out_pa5: xth_out_pa5 {
				pinmux = <PA05_XTH_OUT>;
			};
			/omit-if-no-ref/ lpuart0_cts_pa6: lpuart0_cts_pa6 {
				pinmux = <PA06_LPUART0_CTS>;
			};
			/omit-if-no-ref/ tim4_chb_pa7: tim4_chb_pa7 {
				pinmux = <PA07_TIM4_CHB>;
			};
			/omit-if-no-ref/ tim3_bk_pa8: tim3_bk_pa8 {
				pinmux = <PA08_TIM3_BK>;
			};
			/omit-if-no-ref/ tim5_cha_pa9: tim5_cha_pa9 {
				pinmux = <PA09_TIM5_CHA>;
			};
			/omit-if-no-ref/ tim6_cha_pa10: tim6_cha_pa10 {
				pinmux = <PA10_TIM6_CHA>;
			};
			/omit-if-no-ref/ tim4_chb_pa11: tim4_chb_pa11 {
				pinmux = <PA11_TIM4_CHB>;
			};
			/omit-if-no-ref/ pcnt_s0_pa12: pcnt_s0_pa12 {
				pinmux = <PA12_PCNT_S0>;
			};
			/omit-if-no-ref/ vc2_out_pa13: vc2_out_pa13 {
				pinmux = <PA13_VC2_OUT>;
			};
			/omit-if-no-ref/ pll_out_pa14: pll_out_pa14 {
				pinmux = <PA14_PLL_OUT>;
			};
			/omit-if-no-ref/ pll_out_pb0: pll_out_pb0 {
				pinmux = <PB00_PLL_OUT>;
			};
			/omit-if-no-ref/ tclk_out_pb1: tclk_out_pb1 {
				pinmux = <PB01_TCLK_OUT>;
			};
			/omit-if-no-ref/ tim2_bk_pb2: tim2_bk_pb2 {
				pinmux = <PB02_TIM2_BK>;
			};
			/omit-if-no-ref/ xth_out_pb3: xth_out_pb3 {
				pinmux = <PB03_XTH_OUT>;
			};
			/omit-if-no-ref/ lptim_etr_pb4: lptim_etr_pb4 {
				pinmux = <PB04_LPTIM_ETR>;
			};
			/omit-if-no-ref/ uart0_rts_pb5: uart0_rts_pb5 {
				pinmux = <PB05_UART0_RTS>;
			};
			/omit-if-no-ref/ lptim_tog_pb6: lptim_tog_pb6 {
				pinmux = <PB06_LPTIM_TOG>;
			};
			/omit-if-no-ref/ pcnt_s1_pb7: pcnt_s1_pb7 {
				pinmux = <PB07_PCNT_S1>;
			};
			/omit-if-no-ref/ uart0_txd_pb8: uart0_txd_pb8 {
				pinmux = <PB08_UART0_TXD>;
			};
			/omit-if-no-ref/ uart0_rxd_pb9: uart0_rxd_pb9 {
				pinmux = <PB09_UART0_RXD>;
			};
			/omit-if-no-ref/ uart1_rts_pb10: uart1_rts_pb10 {
				pinmux = <PB10_UART1_RTS>;
			};
			/omit-if-no-ref/ uart1_cts_pb11: uart1_cts_pb11 {
				pinmux = <PB11_UART1_CTS>;
			};
			/omit-if-no-ref/ tim6_cha_pb12: tim6_cha_pb12 {
				pinmux = <PB12_TIM6_CHA>;
			};
			/omit-if-no-ref/ tim6_chb_pb13: tim6_chb_pb13 {
				pinmux = <PB13_TIM6_CHB>;
			};
			/omit-if-no-ref/ tim1_bk_pb14: tim1_bk_pb14 {
				pinmux = <PB14_TIM1_BK>;
			};
			/omit-if-no-ref/ lpuart1_rxd_pb15: lpuart1_rxd_pb15 {
				pinmux = <PB15_LPUART1_RXD>;
			};
			/omit-if-no-ref/ analog_pa0: analog_pa0 {
				pinmux = <PINMUX(GpioPortA, GpioPin0, GpioAfa)>;
			};
			/omit-if-no-ref/ analog_pa1: analog_pa1 {
				pinmux = <PINMUX(GpioPortA, GpioPin1, GpioAfa)>;
			};
			/omit-if-no-ref/ analog_pa2: analog_pa2 {
				pinmux = <PINMUX(GpioPortA, GpioPin2, GpioAfa)>;
			};
			/omit-if-no-ref/ analog_pa3: analog_pa3 {
				pinmux = <PINMUX(GpioPortA, GpioPin3, GpioAfa)>;
			};
			/omit-if-no-ref/ analog_pa4: analog_pa4 {
				pinmux = <PINMUX(GpioPortA, GpioPin4, GpioAfa)>;
			};
			/omit-if-no-ref/ analog_pa5: analog_pa5 {
				pinmux = <PINMUX(GpioPortA, GpioPin5, GpioAfa)>;
			};
			/omit-if-no-ref/ analog_pa6: analog_pa6 {
				pinmux = <PINMUX(GpioPortA, GpioPin6, GpioAfa)>;
			};
			/omit-if-no-ref/ analog_pa7: analog_pa7 {
				pinmux = <PINMUX(GpioPortA, GpioPin7, GpioAfa)>;
			};
			/omit-if-no-ref/ analog_pa8: analog_pa8 {
				pinmux = <PINMUX(GpioPortA, GpioPin8, GpioAfa)>;
			};
			/omit-if-no-ref/ analog_pa9: analog_pa9 {
				pinmux = <PINMUX(GpioPortA, GpioPin9, GpioAfa)>;
			};
			/omit-if-no-ref/ analog_pa10: analog_pa10 {
				pinmux = <PINMUX(GpioPortA, GpioPin10, GpioAfa)>;
			};
			/omit-if-no-ref/ analog_pa11: analog_pa11 {
				pinmux = <PINMUX(GpioPortA, GpioPin11, GpioAfa)>;
			};
			/omit-if-no-ref/ analog_pa12: analog_pa12 {
				pinmux = <PINMUX(GpioPortA, GpioPin12, GpioAfa)>;
			};
			/omit-if-no-ref/ analog_pa13: analog_pa13 {
				pinmux = <PINMUX(GpioPortA, GpioPin13, GpioAfa)>;
			};
			/omit-if-no-ref/ analog_pa14: analog_pa14 {
				pinmux = <PINMUX(GpioPortA, GpioPin14, GpioAfa)>;
			};
			/omit-if-no-ref/ analog_pa15: analog_pa15 {
				pinmux = <PINMUX(GpioPortA, GpioPin15, GpioAfa)>;
			};
			/omit-if-no-ref/ analog_pb0: analog_pb0 {
				pinmux = <PINMUX(GpioPortB, GpioPin0, GpioAfa)>;
			};
			/omit-if-no-ref/ analog_pb1: analog_pb1 {
				pinmux = <PINMUX(GpioPortB, GpioPin1, GpioAfa)>;
			};
			/omit-if-no-ref/ analog_pb2: analog_pb2 {
				pinmux = <PINMUX(GpioPortB, GpioPin2, GpioAfa)>;
			};
			/omit-if-no-ref/ analog_pb3: analog_pb3 {
				pinmux = <PINMUX(GpioPortB, GpioPin3, GpioAfa)>;
			};
			/omit-if-no-ref/ analog_pb4: analog_pb4 {
				pinmux = <PINMUX(GpioPortB, GpioPin4, GpioAfa)>;
			};
			/omit-if-no-ref/ analog_pb5: analog_pb5 {
				pinmux = <PINMUX(GpioPortB, GpioPin5, GpioAfa)>;
			};
			/omit-if-no-ref/ analog_pb6: analog_pb6 {
				pinmux = <PINMUX(GpioPortB, GpioPin6, GpioAfa)>;
			};
			/omit-if-no-ref/ analog_pb7: analog_pb7 {
				pinmux = <PINMUX(GpioPortB, GpioPin7, GpioAfa)>;
			};
			/omit-if-no-ref/ analog_pb8: analog_pb8 {
				pinmux = <PINMUX(GpioPortB, GpioPin8, GpioAfa)>;
			};
			/omit-if-no-ref/ analog_pb9: analog_pb9 {
				pinmux = <PINMUX(GpioPortB, GpioPin9, GpioAfa)>;
			};
			/omit-if-no-ref/ analog_pb10: analog_pb10 {
				pinmux = <PINMUX(GpioPortB, GpioPin10, GpioAfa)>;
			};
			/omit-if-no-ref/ analog_pb11: analog_pb11 {
				pinmux = <PINMUX(GpioPortB, GpioPin11, GpioAfa)>;
			};
			/omit-if-no-ref/ analog_pb12: analog_pb12 {
				pinmux = <PINMUX(GpioPortB, GpioPin12, GpioAfa)>;
			};
			/omit-if-no-ref/ analog_pb13: analog_pb13 {
				pinmux = <PINMUX(GpioPortB, GpioPin13, GpioAfa)>;
			};
			/omit-if-no-ref/ analog_pb14: analog_pb14 {
				pinmux = <PINMUX(GpioPortB, GpioPin14, GpioAfa)>;
			};
			/omit-if-no-ref/ analog_pb15: analog_pb15 {
				pinmux = <PINMUX(GpioPortB, GpioPin15, GpioAfa)>;
			};
			/omit-if-no-ref/ analog_pc0: analog_pc0 {
				pinmux = <PINMUX(GpioPortC, GpioPin0, GpioAfa)>;
			};
			/omit-if-no-ref/ analog_pc1: analog_pc1 {
				pinmux = <PINMUX(GpioPortC, GpioPin1, GpioAfa)>;
			};
			/omit-if-no-ref/ analog_pc2: analog_pc2 {
				pinmux = <PINMUX(GpioPortC, GpioPin2, GpioAfa)>;
			};
			/omit-if-no-ref/ analog_pc3: analog_pc3 {
				pinmux = <PINMUX(GpioPortC, GpioPin3, GpioAfa)>;
			};
			/omit-if-no-ref/ analog_pc4: analog_pc4 {
				pinmux = <PINMUX(GpioPortC, GpioPin4, GpioAfa)>;
			};
			/omit-if-no-ref/ analog_pc5: analog_pc5 {
				pinmux = <PINMUX(GpioPortC, GpioPin5, GpioAfa)>;
			};
			/omit-if-no-ref/ analog_pc6: analog_pc6 {
				pinmux = <PINMUX(GpioPortC, GpioPin6, GpioAfa)>;
			};
			/omit-if-no-ref/ analog_pc7: analog_pc7 {
				pinmux = <PINMUX(GpioPortC, GpioPin7, GpioAfa)>;
			};
			/omit-if-no-ref/ analog_pc8: analog_pc8 {
				pinmux = <PINMUX(GpioPortC, GpioPin8, GpioAfa)>;
			};
			/omit-if-no-ref/ analog_pc9: analog_pc9 {
				pinmux = <PINMUX(GpioPortC, GpioPin9, GpioAfa)>;
			};
			/omit-if-no-ref/ analog_pc10: analog_pc10 {
				pinmux = <PINMUX(GpioPortC, GpioPin10, GpioAfa)>;
			};
			/omit-if-no-ref/ analog_pc11: analog_pc11 {
				pinmux = <PINMUX(GpioPortC, GpioPin11, GpioAfa)>;
			};
			/omit-if-no-ref/ analog_pc12: analog_pc12 {
				pinmux = <PINMUX(GpioPortC, GpioPin12, GpioAfa)>;
			};
			/omit-if-no-ref/ analog_pc13: analog_pc13 {
				pinmux = <PINMUX(GpioPortC, GpioPin13, GpioAfa)>;
			};
			/omit-if-no-ref/ analog_pc14: analog_pc14 {
				pinmux = <PINMUX(GpioPortC, GpioPin14, GpioAfa)>;
			};
			/omit-if-no-ref/ analog_pc15: analog_pc15 {
				pinmux = <PINMUX(GpioPortC, GpioPin15, GpioAfa)>;
			};
			/omit-if-no-ref/ analog_pd0: analog_pd0 {
				pinmux = <PINMUX(GpioPortD, GpioPin0, GpioAfa)>;
			};
			/omit-if-no-ref/ analog_pd1: analog_pd1 {
				pinmux = <PINMUX(GpioPortD, GpioPin1, GpioAfa)>;
			};
			/omit-if-no-ref/ analog_pd2: analog_pd2 {
				pinmux = <PINMUX(GpioPortD, GpioPin2, GpioAfa)>;
			};
			/omit-if-no-ref/ analog_pd3: analog_pd3 {
				pinmux = <PINMUX(GpioPortD, GpioPin3, GpioAfa)>;
			};
			/omit-if-no-ref/ analog_pd4: analog_pd4 {
				pinmux = <PINMUX(GpioPortD, GpioPin4, GpioAfa)>;
			};
			/omit-if-no-ref/ analog_pd5: analog_pd5 {
				pinmux = <PINMUX(GpioPortD, GpioPin5, GpioAfa)>;
			};
			/omit-if-no-ref/ analog_pd6: analog_pd6 {
				pinmux = <PINMUX(GpioPortD, GpioPin6, GpioAfa)>;
			};
			/omit-if-no-ref/ analog_pd7: analog_pd7 {
				pinmux = <PINMUX(GpioPortD, GpioPin7, GpioAfa)>;
			};
			/omit-if-no-ref/ analog_pd8: analog_pd8 {
				pinmux = <PINMUX(GpioPortD, GpioPin8, GpioAfa)>;
			};
			/omit-if-no-ref/ analog_pd9: analog_pd9 {
				pinmux = <PINMUX(GpioPortD, GpioPin9, GpioAfa)>;
			};
			/omit-if-no-ref/ analog_pd10: analog_pd10 {
				pinmux = <PINMUX(GpioPortD, GpioPin10, GpioAfa)>;
			};
			/omit-if-no-ref/ analog_pd11: analog_pd11 {
				pinmux = <PINMUX(GpioPortD, GpioPin11, GpioAfa)>;
			};
			/omit-if-no-ref/ analog_pd12: analog_pd12 {
				pinmux = <PINMUX(GpioPortD, GpioPin12, GpioAfa)>;
			};
			/omit-if-no-ref/ analog_pd13: analog_pd13 {
				pinmux = <PINMUX(GpioPortD, GpioPin13, GpioAfa)>;
			};
			/omit-if-no-ref/ analog_pd14: analog_pd14 {
				pinmux = <PINMUX(GpioPortD, GpioPin14, GpioAfa)>;
			};
			/omit-if-no-ref/ analog_pd15: analog_pd15 {
				pinmux = <PINMUX(GpioPortD, GpioPin15, GpioAfa)>;
			};
			/omit-if-no-ref/ analog_pe0: analog_pe0 {
				pinmux = <PINMUX(GpioPortE, GpioPin0, GpioAfa)>;
			};
			/omit-if-no-ref/ analog_pe1: analog_pe1 {
				pinmux = <PINMUX(GpioPortE, GpioPin1, GpioAfa)>;
			};
			/omit-if-no-ref/ analog_pe2: analog_pe2 {
				pinmux = <PINMUX(GpioPortE, GpioPin2, GpioAfa)>;
			};
			/omit-if-no-ref/ analog_pe3: analog_pe3 {
				pinmux = <PINMUX(GpioPortE, GpioPin3, GpioAfa)>;
			};
			/omit-if-no-ref/ analog_pe4: analog_pe4 {
				pinmux = <PINMUX(GpioPortE, GpioPin4, GpioAfa)>;
			};
			/omit-if-no-ref/ analog_pe5: analog_pe5 {
				pinmux = <PINMUX(GpioPortE, GpioPin5, GpioAfa)>;
			};
			/omit-if-no-ref/ analog_pe6: analog_pe6 {
				pinmux = <PINMUX(GpioPortE, GpioPin6, GpioAfa)>;
			};
			/omit-if-no-ref/ analog_pe7: analog_pe7 {
				pinmux = <PINMUX(GpioPortE, GpioPin7, GpioAfa)>;
			};
			/omit-if-no-ref/ analog_pe8: analog_pe8 {
				pinmux = <PINMUX(GpioPortE, GpioPin8, GpioAfa)>;
			};
			/omit-if-no-ref/ analog_pe9: analog_pe9 {
				pinmux = <PINMUX(GpioPortE, GpioPin9, GpioAfa)>;
			};
			/omit-if-no-ref/ analog_pe10: analog_pe10 {
				pinmux = <PINMUX(GpioPortE, GpioPin10, GpioAfa)>;
			};
			/omit-if-no-ref/ analog_pe11: analog_pe11 {
				pinmux = <PINMUX(GpioPortE, GpioPin11, GpioAfa)>;
			};
			/omit-if-no-ref/ analog_pe12: analog_pe12 {
				pinmux = <PINMUX(GpioPortE, GpioPin12, GpioAfa)>;
			};
			/omit-if-no-ref/ analog_pe13: analog_pe13 {
				pinmux = <PINMUX(GpioPortE, GpioPin13, GpioAfa)>;
			};
			/omit-if-no-ref/ analog_pe14: analog_pe14 {
				pinmux = <PINMUX(GpioPortE, GpioPin14, GpioAfa)>;
			};
			/omit-if-no-ref/ analog_pe15: analog_pe15 {
				pinmux = <PINMUX(GpioPortE, GpioPin15, GpioAfa)>;
			};
			/omit-if-no-ref/ analog_pf0: analog_pf0 {
				pinmux = <PINMUX(GpioPortF, GpioPin0, GpioAfa)>;
			};
			/omit-if-no-ref/ analog_pf1: analog_pf1 {
				pinmux = <PINMUX(GpioPortF, GpioPin1, GpioAfa)>;
			};
			/omit-if-no-ref/ analog_pf2: analog_pf2 {
				pinmux = <PINMUX(GpioPortF, GpioPin2, GpioAfa)>;
			};
			/omit-if-no-ref/ analog_pf3: analog_pf3 {
				pinmux = <PINMUX(GpioPortF, GpioPin3, GpioAfa)>;
			};
			/omit-if-no-ref/ analog_pf4: analog_pf4 {
				pinmux = <PINMUX(GpioPortF, GpioPin4, GpioAfa)>;
			};
			/omit-if-no-ref/ analog_pf5: analog_pf5 {
				pinmux = <PINMUX(GpioPortF, GpioPin5, GpioAfa)>;
			};
			/omit-if-no-ref/ analog_pf6: analog_pf6 {
				pinmux = <PINMUX(GpioPortF, GpioPin6, GpioAfa)>;
			};
			/omit-if-no-ref/ analog_pf7: analog_pf7 {
				pinmux = <PINMUX(GpioPortF, GpioPin7, GpioAfa)>;
			};
			/omit-if-no-ref/ analog_pf8: analog_pf8 {
				pinmux = <PINMUX(GpioPortF, GpioPin8, GpioAfa)>;
			};
			/omit-if-no-ref/ analog_pf9: analog_pf9 {
				pinmux = <PINMUX(GpioPortF, GpioPin9, GpioAfa)>;
			};
			/omit-if-no-ref/ analog_pf10: analog_pf10 {
				pinmux = <PINMUX(GpioPortF, GpioPin10, GpioAfa)>;
			};
			/omit-if-no-ref/ analog_pf11: analog_pf11 {
				pinmux = <PINMUX(GpioPortF, GpioPin11, GpioAfa)>;
			};
			/omit-if-no-ref/ analog_pf12: analog_pf12 {
				pinmux = <PINMUX(GpioPortF, GpioPin12, GpioAfa)>;
			};
			/omit-if-no-ref/ analog_pf13: analog_pf13 {
				pinmux = <PINMUX(GpioPortF, GpioPin13, GpioAfa)>;
			};
			/omit-if-no-ref/ analog_pf14: analog_pf14 {
				pinmux = <PINMUX(GpioPortF, GpioPin14, GpioAfa)>;
			};
			/omit-if-no-ref/ analog_pf15: analog_pf15 {
				pinmux = <PINMUX(GpioPortF, GpioPin15, GpioAfa)>;
			};
		};
	};
};
